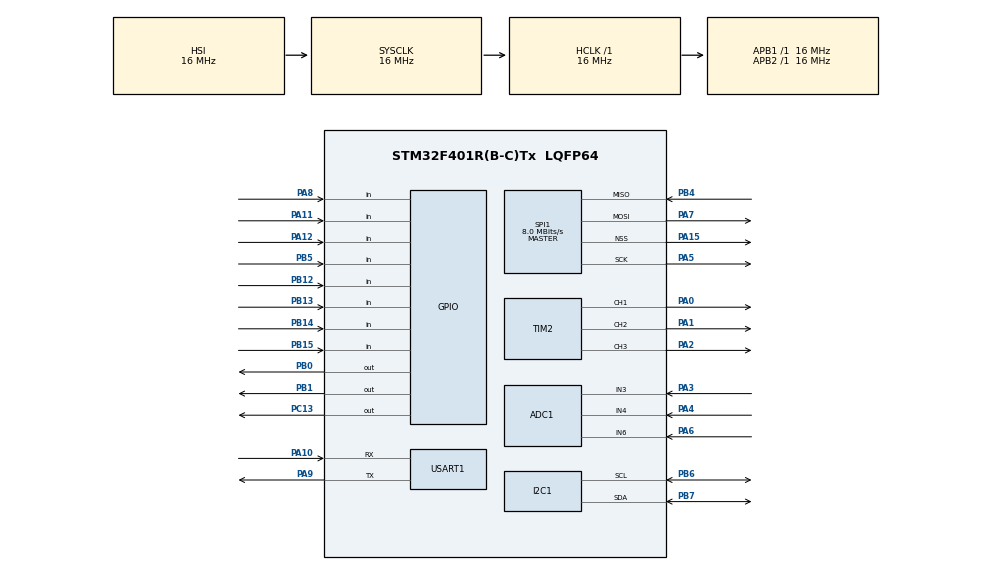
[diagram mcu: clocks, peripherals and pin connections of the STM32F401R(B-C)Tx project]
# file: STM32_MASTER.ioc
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ADC1.Channel-1\#ChannelRegularConversion=ADC_CHANNEL_6
ADC1.Channel-2\#ChannelRegularConversion=ADC_CHANNEL_3
ADC1.Channel-3\#ChannelRegularConversion=ADC_CHANNEL_4
ADC1.ContinuousConvMode=ENABLE
ADC1.DMAContinuousRequests=ENABLE
ADC1.InjNumberOfConversion=0
ADC1.NbrOfConversion=3
ADC1.NbrOfConversionFlag=1
ADC1.Rank-1\#ChannelRegularConversion=1
ADC1.Rank-2\#ChannelRegularConversion=2
ADC1.Rank-3\#ChannelRegularConversion=3
ADC1.SamplingTime-1\#ChannelRegularConversion=ADC_SAMPLETIME_84CYCLES
ADC1.SamplingTime-2\#ChannelRegularConversion=ADC_SAMPLETIME_84CYCLES
ADC1.SamplingTime-3\#ChannelRegularConversion=ADC_SAMPLETIME_84CYCLES
ADC1.ScanConvMode=ENABLE
ADC1.master=1
Dma.ADC1.0.Direction=DMA_PERIPH_TO_MEMORY
Dma.ADC1.0.FIFOMode=DMA_FIFOMODE_DISABLE
Dma.ADC1.0.Instance=DMA2_Stream0
Dma.ADC1.0.MemDataAlignment=DMA_MDATAALIGN_HALFWORD
Dma.ADC1.0.MemInc=DMA_MINC_ENABLE
Dma.ADC1.0.Mode=DMA_NORMAL
Dma.ADC1.0.PeriphDataAlignment=DMA_PDATAALIGN_HALFWORD
Dma.ADC1.0.PeriphInc=DMA_PINC_DISABLE
Dma.ADC1.0.Priority=DMA_PRIORITY_LOW
Dma.Request0=ADC1
FREERTOS.BinarySemaphores01=BinarySem,Dynamic,NULL,Available
FREERTOS.Mutexes01=UART_Mutex,Dynamic,NULL,Available;SPI_Mutex,Dynamic,NULL,Available;Angles_Mutex,Dynamic,NULL,Available
FREERTOS.Queues01=qI2C_LO,16,uint16_t,0,Dynamic,NULL,NULL;qI2C_HI,8,uint16_t,0,Dynamic,NULL,NULL
FREERTOS.Tasks01=defaultTask,24,128,StartDefaultTask,Default,NULL,Dynamic,NULL,NULL;I2C_TX,32,128,Start_I2C_TX,Default,NULL,Dynamic,NULL,NULL;ADCReadTask,8,128,StartADCReadTask,Default,NULL,Dynamic,NULL,NULL;SendAliveTask,8,128,StartSendAliveTask,Default,NULL,Dynamic,NULL,NULL;SpiReadTask,16,128,StartSpiReadTask,Default,NULL,Dynamic,NULL,NULL;ManualModeTask,24,128,StartManualModeTask,Default,NULL,Dynamic,NULL,NULL;AutoModeTask,8,128,StartAutoModeTask,Default,NULL,Dynamic,NULL,NULL;SwitchModeTask,24,128,StartSwitchModeTask,Default,NULL,Dynamic,NULL,NULL;ModeManagerTask,40,128,Start_Mode_Manager_Task,Default,NULL,Dynamic,NULL,NULL;UART_Send_word,8,128,StartUART_Send_word,Default,NULL,Dynamic,NULL,NULL;SPI_SEND,8,128,StartSPI_SEND,Default,NULL,Dynamic,NULL,NULL
FREERTOS.configUSE_NEWLIB_REENTRANT=1
Mcu.Family=STM32F4
Mcu.Name=STM32F401R(B-C)Tx
Mcu.Package=LQFP64
NVIC.DMA2_Stream0_IRQn=true\:5\:0\:false\:false\:true\:true\:false\:true\:true
NVIC.PriorityGroup=NVIC_PRIORITYGROUP_4
NVIC.TIM1_BRK_TIM9_IRQn=true\:15\:0\:false\:false\:true\:false\:false\:true\:true
NVIC.TimeBase=TIM1_BRK_TIM9_IRQn
NVIC.TimeBaseIP=TIM9
PA0-WKUP.Signal=S_TIM2_CH1_ETR
PA1.Signal=S_TIM2_CH2
PA10.Mode=Asynchronous
PA10.Signal=USART1_RX
PA11.GPIO_PuPd=GPIO_PULLUP
PA11.Signal=GPIO_Input
PA12.GPIO_PuPd=GPIO_PULLUP
PA12.Signal=GPIO_Input
PA13.Mode=Trace_Asynchronous_SW
PA13.Signal=SYS_JTMS-SWDIO
PA14.Mode=Trace_Asynchronous_SW
PA14.Signal=SYS_JTCK-SWCLK
PA15.Mode=NSS_Signal_Hard_Output
PA15.Signal=SPI1_NSS
PA2.Signal=S_TIM2_CH3
PA3.Signal=ADCx_IN3
PA4.Signal=ADCx_IN4
PA5.Mode=Full_Duplex_Master
PA5.Signal=SPI1_SCK
PA6.Signal=ADCx_IN6
PA7.Mode=Full_Duplex_Master
PA7.Signal=SPI1_MOSI
PA8.GPIO_PuPd=GPIO_PULLUP
PA8.Signal=GPIO_Input
PA9.Mode=Asynchronous
PA9.Signal=USART1_TX
PB0.Signal=GPIO_Output
PB1.Signal=GPIO_Output
PB12.GPIO_PuPd=GPIO_PULLUP
PB12.Signal=GPIO_Input
PB13.GPIO_PuPd=GPIO_PULLUP
PB13.Signal=GPIO_Input
PB14.GPIO_PuPd=GPIO_PULLUP
PB14.Signal=GPIO_Input
PB15.GPIO_PuPd=GPIO_PULLUP
PB15.Signal=GPIO_Input
PB3.Mode=Trace_Asynchronous_SW
PB3.Signal=SYS_JTDO-SWO
PB4.Mode=Full_Duplex_Master
PB4.Signal=SPI1_MISO
PB5.GPIO_PuPd=GPIO_PULLUP
PB5.Signal=GPIO_Input
PB6.Mode=I2C
PB6.Signal=I2C1_SCL
PB7.Mode=I2C
PB7.Signal=I2C1_SDA
PC13-ANTI_TAMP.Signal=GPIO_Output
ProjectManager.HeapSize=0x200
ProjectManager.StackSize=0x400
ProjectManager.TargetToolchain=STM32CubeIDE
RCC.48MHZClocksFreq_Value=42000000
RCC.AHBFreq_Value=16000000
RCC.APB1Freq_Value=16000000
RCC.APB1TimFreq_Value=16000000
RCC.APB2Freq_Value=16000000
RCC.APB2TimFreq_Value=16000000
RCC.CortexFreq_Value=16000000
RCC.HCLKFreq_Value=16000000
RCC.HSE_VALUE=25000000
RCC.HSI_VALUE=16000000
RCC.LSE_VALUE=32768
RCC.PLLN=168
RCC.SYSCLKFreq_VALUE=16000000
RCC.VCOOutputFreq_Value=168000000
SH.ADCx_IN3.0=ADC1_IN3,IN3
SH.ADCx_IN4.0=ADC1_IN4,IN4
SH.ADCx_IN6.0=ADC1_IN6,IN6
SH.S_TIM2_CH1_ETR.0=TIM2_CH1,PWM Generation1 CH1
SH.S_TIM2_CH2.0=TIM2_CH2,PWM Generation2 CH2
SH.S_TIM2_CH3.0=TIM2_CH3,PWM Generation3 CH3
SPI1.CalculateBaudRate=8.0 MBits/s
SPI1.Direction=SPI_DIRECTION_2LINES
SPI1.Mode=SPI_MODE_MASTER
SPI1.VirtualNSS=VM_NSSHARD
SPI1.VirtualType=VM_MASTER
TIM2.Channel-PWM\ Generation1\ CH1=TIM_CHANNEL_1
TIM2.Channel-PWM\ Generation2\ CH2=TIM_CHANNEL_2
TIM2.Channel-PWM\ Generation3\ CH3=TIM_CHANNEL_3
USART1.VirtualMode=VM_ASYNC
VP_FREERTOS_VS_CMSIS_V2.Mode=CMSIS_V2
VP_SYS_VS_tim9.Mode=TIM9
board=custom

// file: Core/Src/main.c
/* USER CODE BEGIN Header */
/**
 ******************************************************************************
 * @file           : main.c
 * @brief          : Main program body
 ******************************************************************************
 * @attention
 *
 * Copyright (c) 2025 STMicroelectronics.
 * All rights reserved.
 *
 * This software is licensed under terms that can be found in the LICENSE file
 * in the root directory of this software component.
 * If no LICENSE file comes with this software, it is provided AS-IS.
 *
 ******************************************************************************
 */
/* USER CODE END Header */
#include "main.h"
#include "cmsis_os.h"

/* USER CODE BEGIN Includes */
#include "Servo.h"
#include <string.h>
#include <stdio.h>
/* USER CODE END Includes */

/* USER CODE BEGIN PD */
/* Mode constants */
#define MANUAL_MODE        1u
#define AUTO_MODE          0u

/* Edge-triggered requests */
#define EVT_MODE_TOGGLE    (1u << 0)
#define EVT_REQ_AUTO       (1u << 1)
#define EVT_REQ_MANUAL     (1u << 2)
/* Level/state announcements (sticky while active) */
#define EVT_ACTIVE_AUTO    (1u << 3)
#define EVT_ACTIVE_MANUAL  (1u << 4)

/* SPI auto command mapping (0..180 deg) */
#define BYTE_TO_DEG(b)     ((float)(b))     /* assuming AVR already sends 0..180 */
#define ADC_MIN_CAL  100    // set after measuring your endpoint near 0°
#define ADC_MAX_CAL  4000   // set after measuring your endpoint near 180°

/* I2C addressing */
#define I2C_SLAVE_ADDR    0x28

/* I2C TX router */
#define I2C_TX_MAX    64
#define I2C_ADDR8(a7) ((uint16_t)((a7) << 1))
/* USER CODE END PD */

/* USER CODE BEGIN PM */
/* FIX: Use PB2 as manual SPI Chip-Select (software-controlled) */
#define SPI_CS_GPIO_Port   GPIOB
#define SPI_CS_Pin         GPIO_PIN_4
/* USER CODE END PM */

ADC_HandleTypeDef hadc1;
DMA_HandleTypeDef hdma_adc1;

I2C_HandleTypeDef hi2c1;

SPI_HandleTypeDef hspi1;

TIM_HandleTypeDef htim2;

UART_HandleTypeDef huart1;

/* Definitions for defaultTask */
osThreadId_t defaultTaskHandle;
const osThreadAttr_t defaultTask_attributes = {
  .name = "defaultTask",
  .stack_size = 128 * 4,
  .priority = (osPriority_t) osPriorityNormal,
};
/* Definitions for I2C_TX */
osThreadId_t I2C_TXHandle;
const osThreadAttr_t I2C_TX_attributes = {
  .name = "I2C_TX",
  .stack_size = 128 * 4,
  .priority = (osPriority_t) osPriorityAboveNormal,
};
/* Definitions for ADCReadTask */
osThreadId_t ADCReadTaskHandle;
const osThreadAttr_t ADCReadTask_attributes = {
  .name = "ADCReadTask",
  .stack_size = 128 * 4,
  .priority = (osPriority_t) osPriorityLow,
};
/* Definitions for SendAliveTask */
osThreadId_t SendAliveTaskHandle;
const osThreadAttr_t SendAliveTask_attributes = {
  .name = "SendAliveTask",
  .stack_size = 128 * 4,
  .priority = (osPriority_t) osPriorityLow,
};
/* Definitions for SpiReadTask */
osThreadId_t SpiReadTaskHandle;
const osThreadAttr_t SpiReadTask_attributes = {
  .name = "SpiReadTask",
  .stack_size = 128 * 4,
  .priority = (osPriority_t) osPriorityBelowNormal,
};
/* Definitions for ManualModeTask */
osThreadId_t ManualModeTaskHandle;
const osThreadAttr_t ManualModeTask_attributes = {
  .name = "ManualModeTask",
  .stack_size = 128 * 4,
  .priority = (osPriority_t) osPriorityNormal,
};
/* Definitions for AutoModeTask */
osThreadId_t AutoModeTaskHandle;
const osThreadAttr_t AutoModeTask_attributes = {
  .name = "AutoModeTask",
  .stack_size = 128 * 4,
  .priority = (osPriority_t) osPriorityLow,
};
/* Definitions for SwitchModeTask */
osThreadId_t SwitchModeTaskHandle;
const osThreadAttr_t SwitchModeTask_attributes = {
  .name = "SwitchModeTask",
  .stack_size = 128 * 4,
  .priority = (osPriority_t) osPriorityNormal,
};
/* Definitions for ModeManagerTask */
osThreadId_t ModeManagerTaskHandle;
const osThreadAttr_t ModeManagerTask_attributes = {
  .name = "ModeManagerTask",
  .stack_size = 128 * 4,
  .priority = (osPriority_t) osPriorityHigh,
};
/* Definitions for UART_Send_word */
osThreadId_t UART_Send_wordHandle;
const osThreadAttr_t UART_Send_word_attributes = {
  .name = "UART_Send_word",
  .stack_size = 128 * 4,
  .priority = (osPriority_t) osPriorityLow,
};
/* Definitions for SPI_SEND */
osThreadId_t SPI_SENDHandle;
const osThreadAttr_t SPI_SEND_attributes = {
  .name = "SPI_SEND",
  .stack_size = 128 * 4,
  .priority = (osPriority_t) osPriorityLow,
};

/* --------- Our Queues (IDs only, created at runtime) --------- */
/* USER CODE BEGIN PV */
__IO uint16_t g_adc_raw[3] = {0};  // CH3->g_adc_raw[0], CH4->[1], CH5->[2]

/* High/Low I2C queues (router) */
/* FIX: Use ONLY these queue IDs (no CubeMX-generated qI2C_*Handle with wrong sizes) */
osMessageQueueId_t qI2C_HI;
osMessageQueueId_t qI2C_LO;
/* AUTO command queue */
osMessageQueueId_t qAutoCmd;

osMutexId_t UART_MutexHandle;
const osMutexAttr_t UART_Mutex_attributes = {
		.name = "UART_Mutex",
		.attr_bits = osMutexPrioInherit
};
osMutexId_t SPI_MutexHandle;
const osMutexAttr_t SPI_Mutex_attributes = {
		.name = "SPI_Mutex",
		.attr_bits = osMutexPrioInherit
};
osMutexId_t Angles_MutexHandle;
const osMutexAttr_t Angles_Mutex_attributes = {
		.name = "Angles_Mutex",
		.attr_bits = osMutexPrioInherit
};

/* --------- Binary semaphore (speech throttle) --------- */
osSemaphoreId_t BinarySemHandle;
const osSemaphoreAttr_t BinarySem_attributes = {
		.name = "BinarySem"
};

/* --------- Event flags --------- */
osEventFlagsId_t SwitchModeEventHandle;
const osEventFlagsAttr_t SwitchModeEvent_attributes = {
		.name = "SwitchModeEvent"
};

/* Event flags + mode */
volatile uint8_t g_mode = MANUAL_MODE;      /* 1 = manual, 0 = auto */
osEventFlagsId_t evModeFlags;               /* event group shared by tasks */

typedef struct { float inc_deg, hei_deg, dis_deg; } AutoCmd_t;
typedef struct { uint16_t timestamp, counter;} message_t;

/* I2C router message types */
typedef enum {
  I2C_MSG_MANUAL   = 1,   // high priority
  I2C_MSG_HEARTBEAT= 2    // low priority (best-effort)
} I2C_MsgType;

/* I2C router message */
typedef struct {
  I2C_MsgType type;
  uint16_t    addr8;           // 8-bit HAL address (7-bit << 1)
  uint16_t    len;             // <= I2C_TX_MAX
  uint8_t     buf[I2C_TX_MAX]; // inline payload
  uint16_t    timeout_ms;      // per xfer timeout
  uint8_t     retries;         // limited retries on error
} I2C_TxMsg_t;

/* Manual state (kept in sync when AUTO runs) */
static float angle_f_INC = 90.0f;
static float angle_f_HEI = 90.0f;
static float angle_f_DIS = 90.0f;
/* USER CODE END PV */

void SystemClock_Config(void);
static void MX_GPIO_Init(void);
static void MX_DMA_Init(void);
static void MX_I2C1_Init(void);
static void MX_TIM2_Init(void);
static void MX_SPI1_Init(void);
static void MX_ADC1_Init(void);
static void MX_USART1_UART_Init(void);
void StartDefaultTask(void *argument);
void Start_I2C_TX(void *argument);
void StartADCReadTask(void *argument);
void StartSendAliveTask(void *argument);
void StartSpiReadTask(void *argument);
void StartManualModeTask(void *argument);
void StartAutoModeTask(void *argument);
void StartSwitchModeTask(void *argument);
void Start_Mode_Manager_Task(void *argument);
void StartUART_Send_word(void *argument);
void StartSPI_SEND(void *argument);

/* USER CODE BEGIN PFP */
static void AutoMode_Run(float inc_deg, float hei_deg, float dis_deg);
static float map_pot_to_angle(uint16_t raw);

/* I2C TX router APIs */
static osStatus_t I2C_PostHigh(const uint8_t *data, uint16_t n, uint8_t addr7, I2C_MsgType type);
static osStatus_t I2C_PostLowBestEffort(const uint8_t *data, uint16_t n, uint8_t addr7, I2C_MsgType type);
static void I2C_SendTextLN(const char *text);
/* USER CODE END PFP */

/* USER CODE BEGIN 0 */
static void AutoMode_Run(float inc_deg, float hei_deg, float dis_deg)
{
  /* clamp */
  if (inc_deg < 0.f) inc_deg = 0.f;   if (inc_deg > 180.f) inc_deg = 180.f;
  if (hei_deg < 0.f) hei_deg = 0.f;   if (hei_deg > 180.f) hei_deg = 180.f;
  if (dis_deg < 0.f) dis_deg = 0.f;   if (dis_deg > 180.f) dis_deg = 180.f;

  osMutexAcquire(Angles_MutexHandle, osWaitForever);
  Servo_SetAngle   (&htim2, TIM_CHANNEL_1, inc_deg);
  Servo_SetHeight  (&htim2, TIM_CHANNEL_2, hei_deg);
  Servo_SetDistance(&htim2, TIM_CHANNEL_3, dis_deg);
  angle_f_INC = inc_deg;
  angle_f_HEI = hei_deg;
  angle_f_DIS = dis_deg;
  osMutexRelease(Angles_MutexHandle);
}

static float map_pot_to_angle(uint16_t raw)
{
  if (raw < ADC_MIN_CAL) raw = ADC_MIN_CAL;
  if (raw > ADC_MAX_CAL) raw = ADC_MAX_CAL;
  float norm = (float)(raw - ADC_MIN_CAL) / (float)(ADC_MAX_CAL - ADC_MIN_CAL);
  float angle = norm * 180.0f;
  if (angle < 0.0f)   angle = 0.0f;
  if (angle > 180.0f) angle = 180.0f;
  return angle;
}

static osStatus_t I2C_PostHigh(const uint8_t *data, uint16_t n, uint8_t addr7, I2C_MsgType type)
{
  if (!qI2C_HI) return osErrorParameter; /* FIX: guard if queue not created */
  if (n > I2C_TX_MAX) n = I2C_TX_MAX;
  I2C_TxMsg_t m = {0};
  m.type       = type;
  m.addr8      = I2C_ADDR8(addr7);
  m.len        = n;
  memcpy(m.buf, data, n);
  m.timeout_ms = 10;
  m.retries    = 2;
  return osMessageQueuePut(qI2C_HI, &m, 0, 5);   // small wait to ensure delivery
}

static osStatus_t I2C_PostLowBestEffort(const uint8_t *data, uint16_t n, uint8_t addr7, I2C_MsgType type)
{
  if (!qI2C_LO) return osErrorParameter; /* FIX: guard if queue not created */
  if (n > I2C_TX_MAX) n = I2C_TX_MAX;
  I2C_TxMsg_t m = {0};
  m.type       = type;
  m.addr8      = I2C_ADDR8(addr7);
  m.len        = n;
  memcpy(m.buf, data, n);
  m.timeout_ms = 10;
  m.retries    = 1;
  return osMessageQueuePut(qI2C_LO, &m, 0, 0);   // drop if busy
}

static void I2C_SendTextLN(const char *text)
{
  if (!text) return;
  uint8_t buf[I2C_TX_MAX];
  size_t n = strlen(text);
  if (n + 1 > sizeof(buf)) n = sizeof(buf) - 1;
  memcpy(buf, text, n);
  buf[n] = '\n';
  (void)I2C_PostHigh(buf, (uint16_t)(n + 1), I2C_SLAVE_ADDR, I2C_MSG_MANUAL);
}
/* USER CODE END 0 */

int main(void)
{

  /* MCU Configuration--------------------------------------------------------*/

  /* Reset of all peripherals, Initializes the Flash interface and the Systick. */
  HAL_Init();

  /* Configure the system clock */
  SystemClock_Config();

  /* Initialize all configured peripherals */
  MX_GPIO_Init();
  MX_DMA_Init();
  MX_I2C1_Init();
  MX_TIM2_Init();
  MX_SPI1_Init();
  MX_ADC1_Init();
  MX_USART1_UART_Init();
  /* USER CODE BEGIN 2 */
  /* Start PWM on all 3 channels for servos */
  HAL_TIM_PWM_Start(&htim2, TIM_CHANNEL_1);
  HAL_TIM_PWM_Start(&htim2, TIM_CHANNEL_2);
  HAL_TIM_PWM_Start(&htim2, TIM_CHANNEL_3);

  /* Set neutral positions */
  Servo_SetAngle(&htim2,   TIM_CHANNEL_1, angle_f_INC);
  Servo_SetHeight(&htim2,  TIM_CHANNEL_2, angle_f_HEI);
  Servo_SetDistance(&htim2,TIM_CHANNEL_3, angle_f_DIS);

  /* FIX: Ensure manual CS is deasserted (idle high) */
  HAL_GPIO_WritePin(SPI_CS_GPIO_Port, SPI_CS_Pin, GPIO_PIN_SET);

  if (HAL_ADC_Start_DMA(&hadc1, (uint32_t*)g_adc_raw, 3) != HAL_OK) {
    Error_Handler();
  }
  /* USER CODE END 2 */

  /* Init scheduler */
  osKernelInitialize();

  /* -------- Mutexes -------- */
  UART_MutexHandle   = osMutexNew(&UART_Mutex_attributes);
  SPI_MutexHandle    = osMutexNew(&SPI_Mutex_attributes);
  Angles_MutexHandle = osMutexNew(&Angles_Mutex_attributes);

  /* -------- Binary semaphore -------- */
  BinarySemHandle = osSemaphoreNew(1, 1, &BinarySem_attributes);

  /* -------- Queues (create with correct element sizes) -------- */
  /* FIX: Correct queue element sizes and use our queue IDs */
  qI2C_HI  = osMessageQueueNew(8,  sizeof(I2C_TxMsg_t), NULL);
  qI2C_LO  = osMessageQueueNew(16, sizeof(I2C_TxMsg_t), NULL);
  qAutoCmd = osMessageQueueNew(8,  sizeof(AutoCmd_t),    NULL);

  /* -------- Event flags -------- */
  /* FIX: Create event group and set initial MANUAL active */
  evModeFlags = osEventFlagsNew(NULL);
  osEventFlagsSet(evModeFlags, EVT_ACTIVE_MANUAL);
  osEventFlagsClear(evModeFlags, EVT_ACTIVE_AUTO);

  /* -------- Threads -------- */
  defaultTaskHandle    = osThreadNew(StartDefaultTask,        NULL, &defaultTask_attributes);
  I2C_TXHandle         = osThreadNew(Start_I2C_TX,            NULL, &I2C_TX_attributes);
  ADCReadTaskHandle    = osThreadNew(StartADCReadTask,        NULL, &ADCReadTask_attributes);
  SendAliveTaskHandle  = osThreadNew(StartSendAliveTask,      NULL, &SendAliveTask_attributes);
  SpiReadTaskHandle    = osThreadNew(StartSpiReadTask,        NULL, &SpiReadTask_attributes);
  ManualModeTaskHandle = osThreadNew(StartManualModeTask,     NULL, &ManualModeTask_attributes);
  AutoModeTaskHandle   = osThreadNew(StartAutoModeTask,       NULL, &AutoModeTask_attributes);
  SwitchModeTaskHandle = osThreadNew(StartSwitchModeTask,     NULL, &SwitchModeTask_attributes);
  ModeManagerTaskHandle= osThreadNew(Start_Mode_Manager_Task, NULL, &ModeManagerTask_attributes);
  UART_Send_wordHandle = osThreadNew(StartUART_Send_word,     NULL, &UART_Send_word_attributes);
  SPI_SENDHandle       = osThreadNew(StartSPI_SEND,           NULL, &SPI_SEND_attributes);

  /* Start scheduler */
  osKernelStart();

  /* Should never get here */
  while (1) { }
}

void SystemClock_Config(void)
{
  RCC_OscInitTypeDef RCC_OscInitStruct = {0};
  RCC_ClkInitTypeDef RCC_ClkInitStruct = {0};

  /** Configure the main internal regulator output voltage
  */
  __HAL_RCC_PWR_CLK_ENABLE();
  __HAL_PWR_VOLTAGESCALING_CONFIG(PWR_REGULATOR_VOLTAGE_SCALE2);

  /** Initializes the RCC Oscillators */
  RCC_OscInitStruct.OscillatorType = RCC_OSCILLATORTYPE_HSI;
  RCC_OscInitStruct.HSIState = RCC_HSI_ON;
  RCC_OscInitStruct.HSICalibrationValue = RCC_HSICALIBRATION_DEFAULT;
  RCC_OscInitStruct.PLL.PLLState = RCC_PLL_NONE;
  if (HAL_RCC_OscConfig(&RCC_OscInitStruct) != HAL_OK) { Error_Handler(); }

  /** Initializes the CPU, AHB and APB buses clocks */
  RCC_ClkInitStruct.ClockType = RCC_CLOCKTYPE_HCLK|RCC_CLOCKTYPE_SYSCLK
                              |RCC_CLOCKTYPE_PCLK1|RCC_CLOCKTYPE_PCLK2;
  RCC_ClkInitStruct.SYSCLKSource = RCC_SYSCLKSOURCE_HSI;
  RCC_ClkInitStruct.AHBCLKDivider = RCC_SYSCLK_DIV1;
  RCC_ClkInitStruct.APB1CLKDivider = RCC_HCLK_DIV1;
  RCC_ClkInitStruct.APB2CLKDivider = RCC_HCLK_DIV1;
  if (HAL_RCC_ClockConfig(&RCC_ClkInitStruct, FLASH_LATENCY_0) != HAL_OK) { Error_Handler(); }
}

static void MX_ADC1_Init(void)
{
  ADC_ChannelConfTypeDef sConfig = {0};

  hadc1.Instance = ADC1;
  hadc1.Init.ClockPrescaler = ADC_CLOCK_SYNC_PCLK_DIV2;
  hadc1.Init.Resolution = ADC_RESOLUTION_12B;
  hadc1.Init.ScanConvMode = ENABLE;
  hadc1.Init.ContinuousConvMode = ENABLE;
  hadc1.Init.DiscontinuousConvMode = DISABLE;
  hadc1.Init.ExternalTrigConvEdge = ADC_EXTERNALTRIGCONVEDGE_NONE;
  hadc1.Init.ExternalTrigConv = ADC_SOFTWARE_START;
  hadc1.Init.DataAlign = ADC_DATAALIGN_RIGHT;
  hadc1.Init.NbrOfConversion = 3;
  hadc1.Init.DMAContinuousRequests = ENABLE;
  hadc1.Init.EOCSelection = ADC_EOC_SINGLE_CONV;
  if (HAL_ADC_Init(&hadc1) != HAL_OK) { Error_Handler(); }

  sConfig.Channel = ADC_CHANNEL_6;
  sConfig.Rank = 1;
  sConfig.SamplingTime = ADC_SAMPLETIME_84CYCLES;
  if (HAL_ADC_ConfigChannel(&hadc1, &sConfig) != HAL_OK) { Error_Handler(); }

  sConfig.Channel = ADC_CHANNEL_3;
  sConfig.Rank = 2;
  if (HAL_ADC_ConfigChannel(&hadc1, &sConfig) != HAL_OK) { Error_Handler(); }

  sConfig.Channel = ADC_CHANNEL_4;
  sConfig.Rank = 3;
  if (HAL_ADC_ConfigChannel(&hadc1, &sConfig) != HAL_OK) { Error_Handler(); }
}

static void MX_I2C1_Init(void)
{
  hi2c1.Instance = I2C1;
  hi2c1.Init.ClockSpeed = 100000;
  hi2c1.Init.DutyCycle = I2C_DUTYCYCLE_2;
  hi2c1.Init.OwnAddress1 = 0;
  hi2c1.Init.AddressingMode = I2C_ADDRESSINGMODE_7BIT;
  hi2c1.Init.DualAddressMode = I2C_DUALADDRESS_DISABLE;
  hi2c1.Init.OwnAddress2 = 0;
  hi2c1.Init.GeneralCallMode = I2C_GENERALCALL_DISABLE;
  hi2c1.Init.NoStretchMode = I2C_NOSTRETCH_DISABLE;
  if (HAL_I2C_Init(&hi2c1) != HAL_OK) { Error_Handler(); }
}

static void MX_SPI1_Init(void)
{
  /* FIX: Use software NSS so we can drive PB2 manually */
  hspi1.Instance = SPI1;
  hspi1.Init.Mode = SPI_MODE_MASTER;
  hspi1.Init.Direction = SPI_DIRECTION_2LINES;
  hspi1.Init.DataSize = SPI_DATASIZE_8BIT;
  hspi1.Init.CLKPolarity = SPI_POLARITY_LOW;
  hspi1.Init.CLKPhase = SPI_PHASE_1EDGE;
  hspi1.Init.NSS = SPI_NSS_SOFT; /* FIX */
  hspi1.Init.BaudRatePrescaler = SPI_BAUDRATEPRESCALER_2;
  hspi1.Init.FirstBit = SPI_FIRSTBIT_MSB;
  hspi1.Init.TIMode = SPI_TIMODE_DISABLE;
  hspi1.Init.CRCCalculation = SPI_CRCCALCULATION_DISABLE;
  hspi1.Init.CRCPolynomial = 10;
  if (HAL_SPI_Init(&hspi1) != HAL_OK) { Error_Handler(); }
}

static void MX_TIM2_Init(void)
{
  /* FIX: Restore servo-friendly 50 Hz PWM base (1 MHz tick, 20 ms period) */
  TIM_MasterConfigTypeDef sMasterConfig = {0};
  TIM_OC_InitTypeDef sConfigOC = {0};

  htim2.Instance = TIM2;
  htim2.Init.Prescaler = 15;                 /* FIX: 16 MHz / (15+1) = 1 MHz */
  htim2.Init.CounterMode = TIM_COUNTERMODE_UP;
  htim2.Init.Period = 19999;                 /* FIX: 20 ms */
  htim2.Init.ClockDivision = TIM_CLOCKDIVISION_DIV1;
  htim2.Init.AutoReloadPreload = TIM_AUTORELOAD_PRELOAD_DISABLE;
  if (HAL_TIM_PWM_Init(&htim2) != HAL_OK) { Error_Handler(); }

  sMasterConfig.MasterOutputTrigger = TIM_TRGO_RESET;
  sMasterConfig.MasterSlaveMode = TIM_MASTERSLAVEMODE_DISABLE;
  if (HAL_TIMEx_MasterConfigSynchronization(&htim2, &sMasterConfig) != HAL_OK) { Error_Handler(); }

  sConfigOC.OCMode = TIM_OCMODE_PWM1;
  sConfigOC.Pulse = 1500;                    /* FIX: center (1.5 ms) */
  sConfigOC.OCPolarity = TIM_OCPOLARITY_HIGH;
  sConfigOC.OCFastMode = TIM_OCFAST_DISABLE;

  if (HAL_TIM_PWM_ConfigChannel(&htim2, &sConfigOC, TIM_CHANNEL_1) != HAL_OK) { Error_Handler(); }
  if (HAL_TIM_PWM_ConfigChannel(&htim2, &sConfigOC, TIM_CHANNEL_2) != HAL_OK) { Error_Handler(); }
  if (HAL_TIM_PWM_ConfigChannel(&htim2, &sConfigOC, TIM_CHANNEL_3) != HAL_OK) { Error_Handler(); }

  HAL_TIM_MspPostInit(&htim2);
}

static void MX_USART1_UART_Init(void)
{
  huart1.Instance = USART1;
  huart1.Init.BaudRate = 115200;
  huart1.Init.WordLength = UART_WORDLENGTH_8B;
  huart1.Init.StopBits = UART_STOPBITS_1;
  huart1.Init.Parity = UART_PARITY_NONE;
  huart1.Init.Mode = UART_MODE_TX_RX;
  huart1.Init.HwFlowCtl = UART_HWCONTROL_NONE;
  huart1.Init.OverSampling = UART_OVERSAMPLING_16;
  if (HAL_UART_Init(&huart1) != HAL_OK) { Error_Handler(); }
}

static void MX_DMA_Init(void)
{
  __HAL_RCC_DMA2_CLK_ENABLE();
  /* DMA2_Stream0_IRQn interrupt configuration */
  HAL_NVIC_SetPriority(DMA2_Stream0_IRQn, 5, 0);
  HAL_NVIC_EnableIRQ(DMA2_Stream0_IRQn);
}

static void MX_GPIO_Init(void)
{
  GPIO_InitTypeDef GPIO_InitStruct = {0};

  __HAL_RCC_GPIOC_CLK_ENABLE();
  __HAL_RCC_GPIOA_CLK_ENABLE();
  __HAL_RCC_GPIOB_CLK_ENABLE();

  /* PC13 LED */
  HAL_GPIO_WritePin(GPIOC, GPIO_PIN_13, GPIO_PIN_RESET);
  GPIO_InitStruct.Pin = GPIO_PIN_13;
  GPIO_InitStruct.Mode = GPIO_MODE_OUTPUT_PP;
  GPIO_InitStruct.Pull = GPIO_NOPULL;
  GPIO_InitStruct.Speed = GPIO_SPEED_FREQ_LOW;
  HAL_GPIO_Init(GPIOC, &GPIO_InitStruct);

  /* PB0 PB1 outputs */
  HAL_GPIO_WritePin(GPIOB, GPIO_PIN_0|GPIO_PIN_1, GPIO_PIN_RESET);
  GPIO_InitStruct.Pin = GPIO_PIN_0|GPIO_PIN_1;
  GPIO_InitStruct.Mode = GPIO_MODE_OUTPUT_PP;
  GPIO_InitStruct.Pull = GPIO_NOPULL;
  GPIO_InitStruct.Speed = GPIO_SPEED_FREQ_LOW;
  HAL_GPIO_Init(GPIOB, &GPIO_InitStruct);

  /* Buttons: PB12 PB13 PB14 PB15 PB5 with pull-ups */
  GPIO_InitStruct.Pin = GPIO_PIN_12|GPIO_PIN_13|GPIO_PIN_14|GPIO_PIN_15|GPIO_PIN_5;
  GPIO_InitStruct.Mode = GPIO_MODE_INPUT;
  GPIO_InitStruct.Pull = GPIO_PULLUP;
  HAL_GPIO_Init(GPIOB, &GPIO_InitStruct);

  /* Buttons: PA8 PA11 PA12 with pull-ups */
  GPIO_InitStruct.Pin = GPIO_PIN_8|GPIO_PIN_11|GPIO_PIN_12;
  GPIO_InitStruct.Mode = GPIO_MODE_INPUT;
  GPIO_InitStruct.Pull = GPIO_PULLUP;
  HAL_GPIO_Init(GPIOA, &GPIO_InitStruct);

  /* FIX: PB2 as manual SPI CS (idle high) */
  GPIO_InitStruct.Pin = SPI_CS_Pin;
  GPIO_InitStruct.Mode = GPIO_MODE_OUTPUT_PP;
  GPIO_InitStruct.Pull = GPIO_NOPULL;
  GPIO_InitStruct.Speed = GPIO_SPEED_FREQ_LOW;
  HAL_GPIO_Init(SPI_CS_GPIO_Port, &GPIO_InitStruct);
  HAL_GPIO_WritePin(SPI_CS_GPIO_Port, SPI_CS_Pin, GPIO_PIN_SET);
}

void StartDefaultTask(void *argument)
{
  for(;;)
  {
    /* FIX: one-shot startup log on I2C to confirm I2C_TX path */
    static int once = 0;
    if (!once) { I2C_SendTextLN("RTOS up"); once = 1; }
    osDelay(200);
  }
}

void Start_I2C_TX(void *argument)
{
  (void)argument;
  I2C_TxMsg_t msg;

  for (;;)
  {
    /* Prefer high-priority; short block, then try low */
    osStatus_t s = osMessageQueueGet(qI2C_HI, &msg, NULL, 50);
    if (s != osOK) {
      s = osMessageQueueGet(qI2C_LO, &msg, NULL, 50);
      if (s != osOK) continue;
    }

    uint8_t tries = 0;
    for (;;)
    {
      HAL_StatusTypeDef st = HAL_I2C_Master_Transmit(&hi2c1, msg.addr8,
                              (uint8_t*)msg.buf, msg.len, msg.timeout_ms);
      if (st == HAL_OK) break;
      if (++tries > msg.retries) { HAL_GPIO_TogglePin(GPIOC, GPIO_PIN_13); break; }
      osDelay(2);
    }
  }
}

void StartADCReadTask(void *argument)
{
  for(;;)
  {
    uint16_t ch3 = g_adc_raw[0];
    uint16_t ch4 = g_adc_raw[1];
    uint16_t ch5 = g_adc_raw[2];

    float inc = map_pot_to_angle(ch3);
    float hei = map_pot_to_angle(ch4);
    float dis = map_pot_to_angle(ch5);

    /* If you want pots to drive angles continuously, uncomment:
    osMutexAcquire(Angles_MutexHandle, osWaitForever);
    angle_f_INC = inc; angle_f_HEI = hei; angle_f_DIS = dis;
    osMutexRelease(Angles_MutexHandle);
    */

    osDelay(10);
  }
}

void StartSendAliveTask(void *argument)
{
  uint16_t alive_ctr = 0 ;
  uint8_t tx[sizeof(message_t)];    // 4 bytes

  for(;;)
  {
    /* Compose message */
    message_t m;
    m.timestamp = (uint16_t)(HAL_GetTick() & 0xFFFFu);  // wrap every ~65s
    m.counter   = alive_ctr++;

    /* Pack message into bytes (little-endian) */
    tx[0] = (uint8_t)(m.timestamp & 0xFFu);
    tx[1] = (uint8_t)((m.timestamp >> 8) & 0xFFu);
    tx[2] = (uint8_t)(m.counter & 0xFFu);
    tx[3] = (uint8_t)((m.counter >> 8) & 0xFFu);

    /* Enqueue best-effort on LOW queue */
    (void)I2C_PostLowBestEffort(tx, (uint16_t)sizeof(tx), I2C_SLAVE_ADDR, I2C_MSG_HEARTBEAT);

    if (g_mode == AUTO_MODE) {
      I2C_SendTextLN("Now Auto-Mode");
    } else {
      I2C_SendTextLN("Now Manual-Mode");
    }

    osDelay(2000);
  }
}

void StartSpiReadTask(void *argument)
{
  uint8_t rx[3];
  for(;;)
  {
    osMutexAcquire(SPI_MutexHandle, osWaitForever);

    /* FIX: Manual CS low-high around transaction */
    HAL_GPIO_WritePin(SPI_CS_GPIO_Port, SPI_CS_Pin, GPIO_PIN_RESET);
    HAL_StatusTypeDef st = HAL_SPI_Receive(&hspi1, rx, 3, 10);
    /* Wait for bus idle before releasing CS */
    while (__HAL_SPI_GET_FLAG(&hspi1, SPI_FLAG_BSY)) { /* spin ~few cycles */ }
    HAL_GPIO_WritePin(SPI_CS_GPIO_Port, SPI_CS_Pin, GPIO_PIN_SET);

    osMutexRelease(SPI_MutexHandle);

    if (st == HAL_OK)
    {
      AutoCmd_t cmd;
      cmd.inc_deg = BYTE_TO_DEG(rx[0]);  /* incline */
      cmd.hei_deg = BYTE_TO_DEG(rx[1]);  /* height  */
      cmd.dis_deg = BYTE_TO_DEG(rx[2]);  /* distance*/

      if (cmd.inc_deg < 0.f) cmd.inc_deg = 0.f; if (cmd.inc_deg > 180.f) cmd.inc_deg = 180.f;
      if (cmd.hei_deg < 0.f) cmd.hei_deg = 0.f; if (cmd.hei_deg > 180.f) cmd.hei_deg = 180.f;
      if (cmd.dis_deg < 0.f) cmd.dis_deg = 0.f; if (cmd.dis_deg > 180.f) cmd.dis_deg = 180.f;

      (void)osMessageQueuePut(qAutoCmd, &cmd, 0, 0);
    }

    osDelay(10); /* 100 Hz polling */
  }
}

void StartManualModeTask(void *argument)
{
  char msg[48];
  static uint8_t announced = 0;

  for (;;)
  {
    /* Wait until MANUAL is active, but DO NOT clear the flag */
    uint32_t flags = osEventFlagsGet(evModeFlags);
    if ((flags & EVT_ACTIVE_MANUAL) == 0) {
      announced = 0; /* next entry will announce again */
      osEventFlagsWait(evModeFlags, EVT_ACTIVE_MANUAL,
                       osFlagsWaitAny | osFlagsNoClear, osWaitForever);
    }

    /* Announce once per entry into MANUAL (non-blocking if token busy) */
    if (!announced) {
      if (osSemaphoreAcquire(BinarySemHandle, 0) == osOK) {
        I2C_SendTextLN("Switched to Manual mode");
        osSemaphoreRelease(BinarySemHandle);
      }
      announced = 1;
    }

    /* -------- INCLINE (TIM2 CH1) : PB5 inc / PA8 dec -------- */
    if (HAL_GPIO_ReadPin(GPIOB, GPIO_PIN_5) == GPIO_PIN_RESET) /* increase */
    {
      osDelay(20); /* debounce */
      osMutexAcquire(Angles_MutexHandle, osWaitForever);
      angle_f_INC += 5.0f;
      Servo_SetAngle(&htim2, TIM_CHANNEL_1, angle_f_INC);
      osMutexRelease(Angles_MutexHandle);

      if (osSemaphoreAcquire(BinarySemHandle, 0) == osOK) {
        snprintf(msg, sizeof(msg), "incline increased to %d", (int)angle_f_INC);
        I2C_SendTextLN(msg);
        osSemaphoreRelease(BinarySemHandle);
      }

      while (HAL_GPIO_ReadPin(GPIOB, GPIO_PIN_5) == GPIO_PIN_RESET) {
        osDelay(20);
        osMutexAcquire(Angles_MutexHandle, osWaitForever);
        angle_f_INC += 5.0f;
        Servo_SetAngle(&htim2, TIM_CHANNEL_1, angle_f_INC);
        osMutexRelease(Angles_MutexHandle);
      }
    }
    else if (HAL_GPIO_ReadPin(GPIOA, GPIO_PIN_8) == GPIO_PIN_RESET) /* decrease */
    {
      osDelay(20);
      osMutexAcquire(Angles_MutexHandle, osWaitForever);
      angle_f_INC -= 5.0f;
      Servo_SetAngle(&htim2, TIM_CHANNEL_1, angle_f_INC);
      osMutexRelease(Angles_MutexHandle);

      if (osSemaphoreAcquire(BinarySemHandle, 0) == osOK) {
        snprintf(msg, sizeof(msg), "incline decreased to %d", (int)angle_f_INC);
        I2C_SendTextLN(msg);
        osSemaphoreRelease(BinarySemHandle);
      }

      while (HAL_GPIO_ReadPin(GPIOA, GPIO_PIN_8) == GPIO_PIN_RESET) {
        osDelay(20);
        osMutexAcquire(Angles_MutexHandle, osWaitForever);
        angle_f_INC -= 5.0f;
        Servo_SetAngle(&htim2, TIM_CHANNEL_1, angle_f_INC);
        osMutexRelease(Angles_MutexHandle);
      }
    }
    /* -------- HEIGHT (TIM2 CH2) : PB13 inc / PB12 dec -------- */
    else if (HAL_GPIO_ReadPin(GPIOB, GPIO_PIN_13) == GPIO_PIN_RESET) /* increase */
    {
      osDelay(20);
      osMutexAcquire(Angles_MutexHandle, osWaitForever);
      angle_f_HEI += 5.0f;
      Servo_SetHeight(&htim2, TIM_CHANNEL_2, angle_f_HEI);
      osMutexRelease(Angles_MutexHandle);

      if (osSemaphoreAcquire(BinarySemHandle, 0) == osOK) {
        snprintf(msg, sizeof(msg), "height increased to %d", (int)angle_f_HEI);
        I2C_SendTextLN(msg);
        osSemaphoreRelease(BinarySemHandle);
      }

      while (HAL_GPIO_ReadPin(GPIOB, GPIO_PIN_13) == GPIO_PIN_RESET) {
        osDelay(20);
        osMutexAcquire(Angles_MutexHandle, osWaitForever);
        angle_f_HEI += 5.0f;
        Servo_SetHeight(&htim2, TIM_CHANNEL_2, angle_f_HEI);
        osMutexRelease(Angles_MutexHandle);
      }
    }
    else if (HAL_GPIO_ReadPin(GPIOB, GPIO_PIN_12) == GPIO_PIN_RESET) /* decrease */
    {
      osDelay(20);
      osMutexAcquire(Angles_MutexHandle, osWaitForever);
      angle_f_HEI -= 5.0f;
      Servo_SetHeight(&htim2, TIM_CHANNEL_2, angle_f_HEI);
      osMutexRelease(Angles_MutexHandle);

      if (osSemaphoreAcquire(BinarySemHandle, 0) == osOK) {
        snprintf(msg, sizeof(msg), "height decreased to %d", (int)angle_f_HEI);
        I2C_SendTextLN(msg);
        osSemaphoreRelease(BinarySemHandle);
      }

      while (HAL_GPIO_ReadPin(GPIOB, GPIO_PIN_12) == GPIO_PIN_RESET) {
        osDelay(20);
        osMutexAcquire(Angles_MutexHandle, osWaitForever);
        angle_f_HEI -= 5.0f;
        Servo_SetHeight(&htim2, TIM_CHANNEL_2, angle_f_HEI);
        osMutexRelease(Angles_MutexHandle);
      }
    }
    /* -------- DISTANCE (TIM2 CH3) : PB15 inc / PB14 dec -------- */
    else if (HAL_GPIO_ReadPin(GPIOB, GPIO_PIN_15) == GPIO_PIN_RESET) /* increase */
    {
      osDelay(20);
      osMutexAcquire(Angles_MutexHandle, osWaitForever);
      angle_f_DIS += 5.0f;
      Servo_SetDistance(&htim2, TIM_CHANNEL_3, angle_f_DIS);
      osMutexRelease(Angles_MutexHandle);

      if (osSemaphoreAcquire(BinarySemHandle, 0) == osOK) {
        snprintf(msg, sizeof(msg), "Slide increased to %d", (int)angle_f_DIS);
        I2C_SendTextLN(msg);
        osSemaphoreRelease(BinarySemHandle);
      }

      while (HAL_GPIO_ReadPin(GPIOB, GPIO_PIN_15) == GPIO_PIN_RESET) {
        osDelay(20);
        osMutexAcquire(Angles_MutexHandle, osWaitForever);
        angle_f_DIS += 5.0f;
        Servo_SetDistance(&htim2, TIM_CHANNEL_3, angle_f_DIS);
        osMutexRelease(Angles_MutexHandle);
      }
    }
    else if (HAL_GPIO_ReadPin(GPIOB, GPIO_PIN_14) == GPIO_PIN_RESET) /* decrease */
    {
      osDelay(20);
      osMutexAcquire(Angles_MutexHandle, osWaitForever);
      angle_f_DIS -= 5.0f;
      Servo_SetDistance(&htim2, TIM_CHANNEL_3, angle_f_DIS);
      osMutexRelease(Angles_MutexHandle);

      if (osSemaphoreAcquire(BinarySemHandle, 0) == osOK) {
        snprintf(msg, sizeof(msg), "Slide decreased to %d", (int)angle_f_DIS);
        I2C_SendTextLN(msg);
        osSemaphoreRelease(BinarySemHandle);
      }

      while (HAL_GPIO_ReadPin(GPIOB, GPIO_PIN_14) == GPIO_PIN_RESET) {
        osDelay(20);
        osMutexAcquire(Angles_MutexHandle, osWaitForever);
        angle_f_DIS -= 5.0f;
        Servo_SetDistance(&htim2, TIM_CHANNEL_3, angle_f_DIS);
        osMutexRelease(Angles_MutexHandle);
      }
    }

    osDelay(5); /* yield */
  }
}

void StartAutoModeTask(void *argument)
{
  AutoCmd_t cmd = {90,90,90};
  for(;;)
  {
    /* Wait until AUTO is active */
    osEventFlagsWait(evModeFlags, EVT_ACTIVE_AUTO, osFlagsWaitAny, osWaitForever);

    if( g_mode == AUTO_MODE){
      osDelay(20);
      I2C_SendTextLN("Switched to Auto mode");
    }

    /* Use latest command if available */
    (void)osMessageQueueGet(qAutoCmd, &cmd, NULL, 0);
    AutoMode_Run(cmd.inc_deg, cmd.hei_deg, cmd.dis_deg);

    osDelay(5);
  }
}

void StartSwitchModeTask(void *argument)
{
  for(;;)
  {
    /* Example: PA12 pressed = toggle request (active low) */
    if (HAL_GPIO_ReadPin(GPIOA, GPIO_PIN_12) == GPIO_PIN_RESET) {
      osDelay(100);
      osEventFlagsSet(evModeFlags, EVT_MODE_TOGGLE);

      osDelay(5); /* debounce */
      if (g_mode == AUTO_MODE){
        HAL_GPIO_WritePin(GPIOB, GPIO_PIN_1, GPIO_PIN_SET);
        HAL_GPIO_WritePin(GPIOB, GPIO_PIN_0, GPIO_PIN_RESET);
      }
      else if(g_mode == MANUAL_MODE) {
        HAL_GPIO_WritePin(GPIOB, GPIO_PIN_1, GPIO_PIN_RESET);
        HAL_GPIO_WritePin(GPIOB, GPIO_PIN_0, GPIO_PIN_SET);
      }
    }
    osDelay(5);
  }
}

void Start_Mode_Manager_Task(void *argument)
{
  for(;;)
  {
    /* Wait for any mode request; don't auto-clear so we can inspect bits */
    uint32_t got = osEventFlagsWait(
        evModeFlags,
        EVT_MODE_TOGGLE | EVT_REQ_AUTO | EVT_REQ_MANUAL,
        osFlagsWaitAny | osFlagsNoClear,
        osWaitForever);

    /* Consume edge events */
    osEventFlagsClear(evModeFlags, EVT_MODE_TOGGLE | EVT_REQ_AUTO | EVT_REQ_MANUAL);

    uint8_t next = g_mode;
    if (got & EVT_MODE_TOGGLE)  next = (g_mode == MANUAL_MODE) ? AUTO_MODE : MANUAL_MODE;
    if (got & EVT_REQ_AUTO)     next = AUTO_MODE;
    if (got & EVT_REQ_MANUAL)   next = MANUAL_MODE;

    if (next != g_mode) {
      g_mode = next;
      if (g_mode == AUTO_MODE) {
        osEventFlagsClear(evModeFlags, EVT_ACTIVE_MANUAL);
        osEventFlagsSet  (evModeFlags, EVT_ACTIVE_AUTO);
      } else {
        osEventFlagsClear(evModeFlags, EVT_ACTIVE_AUTO);
        osEventFlagsSet  (evModeFlags, EVT_ACTIVE_MANUAL);
      }
    }
  }
}

void StartUART_Send_word(void *argument)
{
  uint8_t msg[] = "A\r"; /* 2 bytes */

  for(;;)
  {
    osMutexAcquire(UART_MutexHandle, osWaitForever);
    (void)HAL_UART_Transmit(&huart1, msg, (uint16_t)(sizeof(msg)-1), 10);
    osMutexRelease(UART_MutexHandle);
    osDelay(1000);
  }
}

void StartSPI_SEND(void *argument)
{
  uint8_t Tx[3]= "ABC";
  for(;;)
  {
    osMutexAcquire(SPI_MutexHandle, osWaitForever);

    /* FIX: Manual CS low-high around transmit */
    HAL_GPIO_WritePin(SPI_CS_GPIO_Port, SPI_CS_Pin, GPIO_PIN_RESET);
    (void)HAL_SPI_Transmit(&hspi1, Tx, 3, 100);
    while (__HAL_SPI_GET_FLAG(&hspi1, SPI_FLAG_BSY)) { /* wait idle */ }
    HAL_GPIO_WritePin(SPI_CS_GPIO_Port, SPI_CS_Pin, GPIO_PIN_SET);

    osMutexRelease(SPI_MutexHandle);

    osDelay(10); /* FIX: avoid hammering the bus too fast */
  }
}

void HAL_TIM_PeriodElapsedCallback(TIM_HandleTypeDef *htim)
{
  if (htim->Instance == TIM9) {
    HAL_IncTick();
  }
}

void Error_Handler(void)
{
  __disable_irq();
  while (1) { }
}
